AUTOSAR XML (schema 00044)
package /ComponentTypes
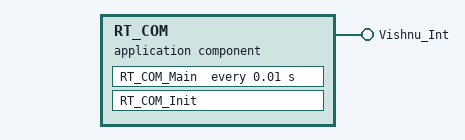
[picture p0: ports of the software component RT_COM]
  application sw component type RT_COM
    provide port Vishnu_Int: nonqueued-sender-com-spec{data-element=Vishnu_Data, init-value=fields=[0, 0]}, provided-interface=Vishnu_Int
    behavior RT_COM_InternalBehavior: data-type-mapping=RT_COM
      init event RT_COM_InitEvent: start-on-event=RT_COM_Init
      timing event TMT_RT_COM_Main: start-on-event=RT_COM_Main, period=0.01
      runnable RT_COM_Init
      runnable RT_COM_Main
  swc implementation RT_COM_Implementation: behavior=RT_COM_InternalBehavior
